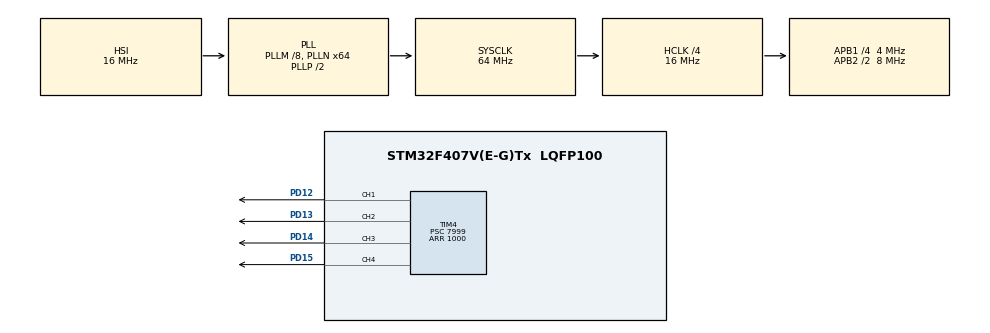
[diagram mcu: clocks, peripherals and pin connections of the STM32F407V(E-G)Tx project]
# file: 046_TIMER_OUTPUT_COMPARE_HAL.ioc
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Mcu.Family=STM32F4
Mcu.Name=STM32F407V(E-G)Tx
Mcu.Package=LQFP100
NVIC.PriorityGroup=NVIC_PRIORITYGROUP_0
PD12.Signal=S_TIM4_CH1
PD13.Signal=S_TIM4_CH2
PD14.Signal=S_TIM4_CH3
PD15.Signal=S_TIM4_CH4
PH0-OSC_IN.Mode=HSE-External-Oscillator
PH0-OSC_IN.Signal=RCC_OSC_IN
PH1-OSC_OUT.Mode=HSE-External-Oscillator
PH1-OSC_OUT.Signal=RCC_OSC_OUT
ProjectManager.HeapSize=0x200
ProjectManager.StackSize=0x400
ProjectManager.TargetToolchain=STM32CubeIDE
RCC.48MHZClocksFreq_Value=18285714.285714287
RCC.AHBCLKDivider=RCC_SYSCLK_DIV4
RCC.AHBFreq_Value=16000000
RCC.APB1CLKDivider=RCC_HCLK_DIV4
RCC.APB1Freq_Value=4000000
RCC.APB1TimFreq_Value=8000000
RCC.APB2CLKDivider=RCC_HCLK_DIV2
RCC.APB2Freq_Value=8000000
RCC.APB2TimFreq_Value=16000000
RCC.CortexFreq_Value=16000000
RCC.HCLKFreq_Value=16000000
RCC.HSE_VALUE=8000000
RCC.HSI_VALUE=16000000
RCC.LSE_VALUE=32768
RCC.PLLM=8
RCC.PLLN=64
RCC.PLLQ=7
RCC.SYSCLKFreq_VALUE=64000000
RCC.SYSCLKSource=RCC_SYSCLKSOURCE_PLLCLK
RCC.VCOOutputFreq_Value=128000000
SH.S_TIM4_CH1.0=TIM4_CH1,Output Compare1 CH1
SH.S_TIM4_CH2.0=TIM4_CH2,Output Compare2 CH2
SH.S_TIM4_CH3.0=TIM4_CH3,Output Compare3 CH3
SH.S_TIM4_CH4.0=TIM4_CH4,Output Compare4 CH4
TIM4.Channel-Output\ Compare1\ CH1=TIM_CHANNEL_1
TIM4.Channel-Output\ Compare2\ CH2=TIM_CHANNEL_2
TIM4.Channel-Output\ Compare3\ CH3=TIM_CHANNEL_3
TIM4.Channel-Output\ Compare4\ CH4=TIM_CHANNEL_4
TIM4.OCMode_1=TIM_OCMODE_TOGGLE
TIM4.OCMode_2=TIM_OCMODE_TOGGLE
TIM4.OCMode_3=TIM_OCMODE_TOGGLE
TIM4.OCMode_4=TIM_OCMODE_TOGGLE
TIM4.OCPolarity_2=TIM_OCPOLARITY_HIGH
TIM4.Period=1000
TIM4.Prescaler=7999
TIM4.Pulse-Output\ Compare1\ CH1=250
TIM4.Pulse-Output\ Compare2\ CH2=500
TIM4.Pulse-Output\ Compare3\ CH3=750
TIM4.Pulse-Output\ Compare4\ CH4=1000
VP_TIM4_VS_ClockSourceINT.Mode=Internal
board=STM32F407G-DISC1

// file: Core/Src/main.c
/* USER CODE BEGIN Header */
/**
  ******************************************************************************
  * @file           : main.c
  * @brief          : Main program body
  ******************************************************************************
  * @attention
  *
  * Copyright (c) 2024 STMicroelectronics.
  * All rights reserved.
  *
  * This software is licensed under terms that can be found in the LICENSE file
  * in the root directory of this software component.
  * If no LICENSE file comes with this software, it is provided AS-IS.
  *
  ******************************************************************************
  */
/* USER CODE END Header */
#include "main.h"

TIM_HandleTypeDef htim4;

void SystemClock_Config(void);
static void MX_GPIO_Init(void);
static void MX_TIM4_Init(void);

int main(void)
{

  /* MCU Configuration--------------------------------------------------------*/

  /* Reset of all peripherals, Initializes the Flash interface and the Systick. */
  HAL_Init();

  /* Configure the system clock */
  SystemClock_Config();

  /* Initialize all configured peripherals */
  MX_GPIO_Init();
  MX_TIM4_Init();

  /* Infinite loop */
  /* USER CODE BEGIN WHILE */

	HAL_TIM_OC_Start(&htim4, TIM_CHANNEL_1);	//->The Channel 1 of TIM4 active (Pin is D12)
	HAL_TIM_OC_Start(&htim4, TIM_CHANNEL_2);	//->The Channel 2 of TIM4 active (Pin is D13)
	HAL_TIM_OC_Start(&htim4, TIM_CHANNEL_3);	//->The Channel 3 of TIM4 active (Pin is D14)
	HAL_TIM_OC_Start(&htim4, TIM_CHANNEL_4);	//->The Channel 4 of TIM4 active (Pin is D15)

	while (1)
	{
    /* USER CODE END WHILE */

	}
}

void SystemClock_Config(void)
{
  RCC_OscInitTypeDef RCC_OscInitStruct = {0};
  RCC_ClkInitTypeDef RCC_ClkInitStruct = {0};

  /** Configure the main internal regulator output voltage
  */
  __HAL_RCC_PWR_CLK_ENABLE();
  __HAL_PWR_VOLTAGESCALING_CONFIG(PWR_REGULATOR_VOLTAGE_SCALE1);

  /** Initializes the RCC Oscillators according to the specified parameters
  * in the RCC_OscInitTypeDef structure.
  */
  RCC_OscInitStruct.OscillatorType = RCC_OSCILLATORTYPE_HSI;
  RCC_OscInitStruct.HSIState = RCC_HSI_ON;
  RCC_OscInitStruct.HSICalibrationValue = RCC_HSICALIBRATION_DEFAULT;
  RCC_OscInitStruct.PLL.PLLState = RCC_PLL_ON;
  RCC_OscInitStruct.PLL.PLLSource = RCC_PLLSOURCE_HSI;
  RCC_OscInitStruct.PLL.PLLM = 8;
  RCC_OscInitStruct.PLL.PLLN = 64;
  RCC_OscInitStruct.PLL.PLLP = RCC_PLLP_DIV2;
  RCC_OscInitStruct.PLL.PLLQ = 7;
  if (HAL_RCC_OscConfig(&RCC_OscInitStruct) != HAL_OK)
  {
    Error_Handler();
  }

  /** Initializes the CPU, AHB and APB buses clocks
  */
  RCC_ClkInitStruct.ClockType = RCC_CLOCKTYPE_HCLK|RCC_CLOCKTYPE_SYSCLK
                              |RCC_CLOCKTYPE_PCLK1|RCC_CLOCKTYPE_PCLK2;
  RCC_ClkInitStruct.SYSCLKSource = RCC_SYSCLKSOURCE_PLLCLK;
  RCC_ClkInitStruct.AHBCLKDivider = RCC_SYSCLK_DIV4;
  RCC_ClkInitStruct.APB1CLKDivider = RCC_HCLK_DIV4;
  RCC_ClkInitStruct.APB2CLKDivider = RCC_HCLK_DIV2;

  if (HAL_RCC_ClockConfig(&RCC_ClkInitStruct, FLASH_LATENCY_0) != HAL_OK)
  {
    Error_Handler();
  }
}

static void MX_TIM4_Init(void)
{

  TIM_ClockConfigTypeDef sClockSourceConfig = {0};
  TIM_MasterConfigTypeDef sMasterConfig = {0};
  TIM_OC_InitTypeDef sConfigOC = {0};

  htim4.Instance = TIM4;
  htim4.Init.Prescaler = 7999;
  htim4.Init.CounterMode = TIM_COUNTERMODE_UP;
  htim4.Init.Period = 1000;
  htim4.Init.ClockDivision = TIM_CLOCKDIVISION_DIV1;
  htim4.Init.AutoReloadPreload = TIM_AUTORELOAD_PRELOAD_DISABLE;
  if (HAL_TIM_Base_Init(&htim4) != HAL_OK)
  {
    Error_Handler();
  }
  sClockSourceConfig.ClockSource = TIM_CLOCKSOURCE_INTERNAL;
  if (HAL_TIM_ConfigClockSource(&htim4, &sClockSourceConfig) != HAL_OK)
  {
    Error_Handler();
  }
  if (HAL_TIM_OC_Init(&htim4) != HAL_OK)
  {
    Error_Handler();
  }
  sMasterConfig.MasterOutputTrigger = TIM_TRGO_RESET;
  sMasterConfig.MasterSlaveMode = TIM_MASTERSLAVEMODE_DISABLE;
  if (HAL_TIMEx_MasterConfigSynchronization(&htim4, &sMasterConfig) != HAL_OK)
  {
    Error_Handler();
  }
  sConfigOC.OCMode = TIM_OCMODE_TOGGLE;
  sConfigOC.Pulse = 250;
  sConfigOC.OCPolarity = TIM_OCPOLARITY_HIGH;
  sConfigOC.OCFastMode = TIM_OCFAST_DISABLE;
  if (HAL_TIM_OC_ConfigChannel(&htim4, &sConfigOC, TIM_CHANNEL_1) != HAL_OK)
  {
    Error_Handler();
  }
  sConfigOC.Pulse = 500;
  if (HAL_TIM_OC_ConfigChannel(&htim4, &sConfigOC, TIM_CHANNEL_2) != HAL_OK)
  {
    Error_Handler();
  }
  sConfigOC.Pulse = 750;
  if (HAL_TIM_OC_ConfigChannel(&htim4, &sConfigOC, TIM_CHANNEL_3) != HAL_OK)
  {
    Error_Handler();
  }
  sConfigOC.Pulse = 1000;
  if (HAL_TIM_OC_ConfigChannel(&htim4, &sConfigOC, TIM_CHANNEL_4) != HAL_OK)
  {
    Error_Handler();
  }
  HAL_TIM_MspPostInit(&htim4);

}

static void MX_GPIO_Init(void)
{

  /* GPIO Ports Clock Enable */
  __HAL_RCC_GPIOH_CLK_ENABLE();
  __HAL_RCC_GPIOD_CLK_ENABLE();

}

void Error_Handler(void)
{
  __disable_irq();
  while (1)
  {
  }
}
